# MCXN236 register map
Vendor: nxp.com; File version: 1.0
CPU: CM33 r2p0, little endian, MPU, FPU, VTOR, 3 interrupt priority bits
Registers are 32-bit, read-write, reset 0x0 unless marked. A register's access mark holds for its fields unless they carry their own. Offsets are from the block's base; [hi:lo] are bit positions; 'fields as' and 'values as' point back to an identical list; <NAME> marks a mode.

## USBPHY
Base 0x4010A000; alternate view of USBHS1_PHY_DCD
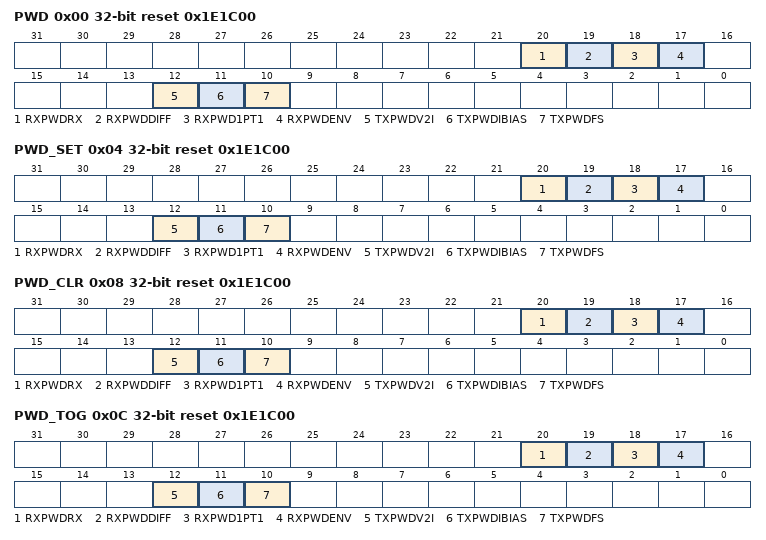
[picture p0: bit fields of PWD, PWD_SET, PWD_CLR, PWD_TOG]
0x00 PWD reset 0x1E1C00 — Power Down Register
  [20] RXPWDRX — Power down USBPHY receiver circuits except the FS differential comparator
    0=RX_BIAS_ENABLE (Enable the PHY's receiver block except for the FS differential receiver); 1=RX_BIAS_PWD (Power down the PHY's receiver block except for the FS differential receiver)
  [19] RXPWDDIFF — Power down USB HS differential receiver
    0=HS_RXDIFF_ENABLE (Enable the HS differential receiver); 1=HS_RXDIFF_PWD (Power down the HS differential receiver)
  [18] RXPWD1PT1 — Power down USB FS differential receiver
    0=FS_RXDIFF_ENABLE (Enable the FS differential receiver); 1=FS_RXDIFF_PWD (Power down the FS differential receiver)
  [17] RXPWDENV — Power down USB HS receiver envelope detector and Host Disconnect comparator
    0=RX_ENVHD_ENABLE (Enable the HS Rx envelope detector and Host Disconnect comparator); 1=RX_ENVHD_PWD (Power down the HS Rx envelope detector and Host Disconnect comparator)
  [12] TXPWDV2I — Power down USBPHY V-I converter and current mirror
    0=V2I_BIAS_ENABLE (Enable Tx V-to-I converter and current mirrors); 1=V2I_BIAS_PWD (Power down Tx V-to-I converter and current mirrors)
  [11] TXPWDIBIAS — Power down USBPHY current bias block
    0=IBIAS_ENABLE (Enable current mirror circuits for general transceiver/detector bias); 1=IBIAS_PWD (Power down current bias mirrors)
  [10] TXPWDFS — Power down USB FS drivers
    0=FSTX_BIAS_ENABLE (Provide bias to allow enable of FS Tx drivers); 1=FSTX_BIAS_PWD (Power down FS Tx drivers and configure them to high impedance state)
0x04 PWD_SET reset 0x1E1C00 write-1-sets — Power Down Register
  [20] RXPWDRX write-1-sets — Power down USBPHY receiver circuits except the FS differential comparator
  [19] RXPWDDIFF write-1-sets — Power down USB HS differential receiver
  [18] RXPWD1PT1 write-1-sets — Power down USB FS differential receiver
  [17] RXPWDENV write-1-sets — Power down USB HS receiver envelope detector and Host Disconnect comparator
  [12] TXPWDV2I write-1-sets — Power down USBPHY V-I converter and current mirror
  [11] TXPWDIBIAS write-1-sets — Power down USBPHY current bias block
  [10] TXPWDFS write-1-sets — Power down USB FS drivers
0x08 PWD_CLR reset 0x1E1C00 write-1-clears — Power Down Register
  [20] RXPWDRX write-1-clears — Power down USBPHY receiver circuits except the FS differential comparator
  [19] RXPWDDIFF write-1-clears — Power down USB HS differential receiver
  [18] RXPWD1PT1 write-1-clears — Power down USB FS differential receiver
  [17] RXPWDENV write-1-clears — Power down USB HS receiver envelope detector and Host Disconnect comparator
  [12] TXPWDV2I write-1-clears — Power down USBPHY V-I converter and current mirror
  [11] TXPWDIBIAS write-1-clears — Power down USBPHY current bias block
  [10] TXPWDFS write-1-clears — Power down USB FS drivers
0x0C PWD_TOG reset 0x1E1C00 write-1-toggles — Power Down Register
  [20] RXPWDRX write-1-toggles — Power down USBPHY receiver circuits except the FS differential comparator
  [19] RXPWDDIFF write-1-toggles — Power down USB HS differential receiver
  [18] RXPWD1PT1 write-1-toggles — Power down USB FS differential receiver
  [17] RXPWDENV write-1-toggles — Power down USB HS receiver envelope detector and Host Disconnect comparator
  [12] TXPWDV2I write-1-toggles — Power down USBPHY V-I converter and current mirror
  [11] TXPWDIBIAS write-1-toggles — Power down USBPHY current bias block
  [10] TXPWDFS write-1-toggles — Power down USB FS drivers
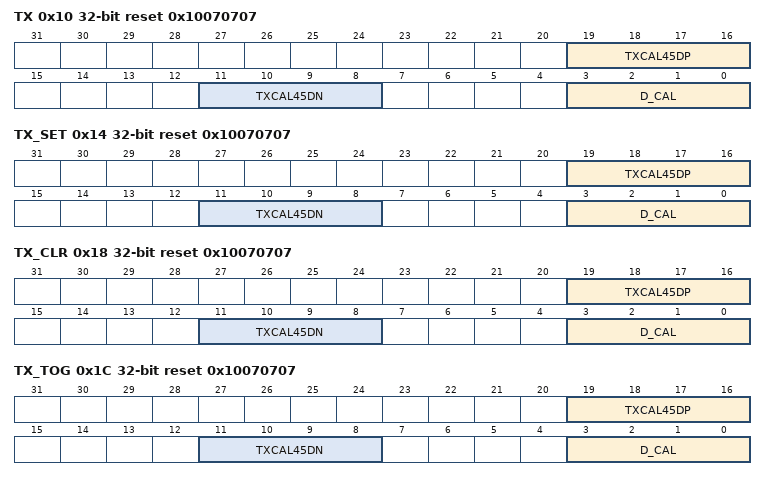
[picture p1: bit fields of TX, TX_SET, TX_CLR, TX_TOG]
0x10 TX reset 0x10070707 — Tx Control Register
  [19:16] TXCAL45DP — DP series termination resistance trim
  [11:8] TXCAL45DN — DM series termination resistance trim
  [3:0] D_CAL — HS Tx output current trim
0x14 TX_SET reset 0x10070707 write-1-sets — Tx Control Register
  [19:16] TXCAL45DP write-1-sets — DP series termination resistance trim
  [11:8] TXCAL45DN write-1-sets — DM series termination resistance trim
  [3:0] D_CAL write-1-sets — HS Tx output current trim
0x18 TX_CLR reset 0x10070707 write-1-clears — Tx Control Register
  [19:16] TXCAL45DP write-1-clears — DP series termination resistance trim
  [11:8] TXCAL45DN write-1-clears — DM series termination resistance trim
  [3:0] D_CAL write-1-clears — HS Tx output current trim
0x1C TX_TOG reset 0x10070707 write-1-toggles — Tx Control Register
  [19:16] TXCAL45DP write-1-toggles — DP series termination resistance trim
  [11:8] TXCAL45DN write-1-toggles — DM series termination resistance trim
  [3:0] D_CAL write-1-toggles — HS Tx output current trim
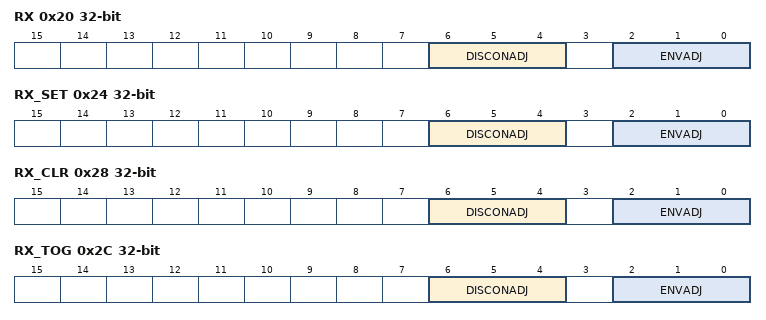
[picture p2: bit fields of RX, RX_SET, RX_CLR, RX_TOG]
0x20 RX — Rx Control Register
  [6:4] DISCONADJ — Disconnect detector trip point
    0=DISCON_TRIM_NOM (Trip-Level Voltage is 0.56875 V); 1=DISCON_TRIM_LO (Trip-Level Voltage is 0.55000 V); 2=DISCON_TRIM_MEDHI (Trip-Level Voltage is 0.58125 V); 3=DISCON_TRIM_HI (Trip-Level Voltage is 0.60000 V)
  [2:0] ENVADJ — Envelope detector trip point
    0=ENV_TRIM_NOM (Trip-Level Voltage is 0.1000 V); 1=ENV_TRIM_MEDHI (Trip-Level Voltage is 0.1125 V); 2=ENV_TRIM_HI (Trip-Level Voltage is 0.1250 V); 3=ENV_TRIM_LO (Trip-Level Voltage is 0.0875 V)
0x24 RX_SET write-1-sets — Rx Control Register
  [6:4] DISCONADJ write-1-sets — Disconnect detector trip point
  [2:0] ENVADJ write-1-sets — Envelope detector trip point
0x28 RX_CLR write-1-clears — Rx Control Register
  [6:4] DISCONADJ write-1-clears — Disconnect detector trip point
  [2:0] ENVADJ write-1-clears — Envelope detector trip point
0x2C RX_TOG write-1-toggles — Rx Control Register
  [6:4] DISCONADJ write-1-toggles — Disconnect detector trip point
  [2:0] ENVADJ write-1-toggles — Envelope detector trip point
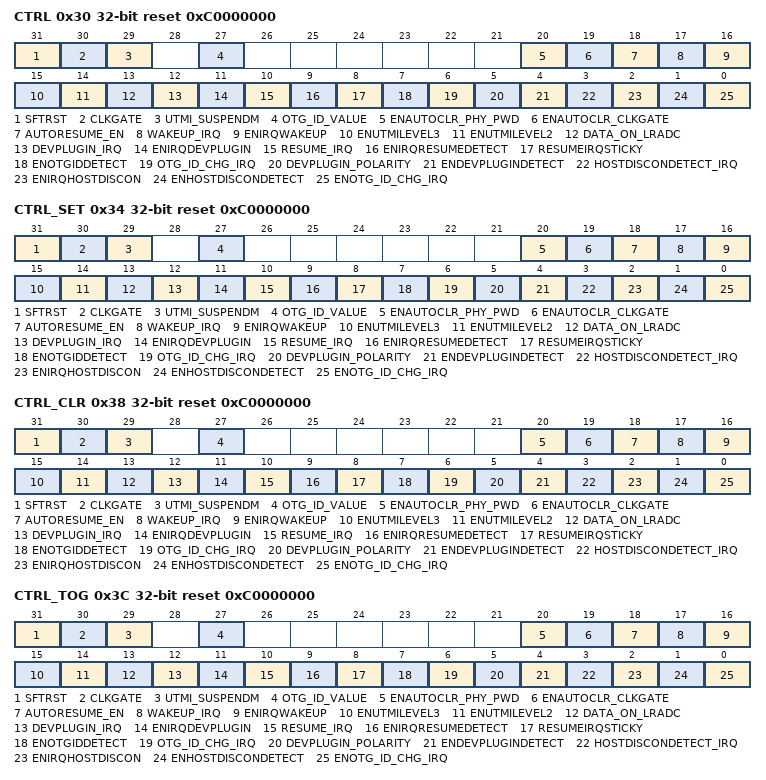
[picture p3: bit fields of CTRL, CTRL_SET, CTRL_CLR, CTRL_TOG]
0x30 CTRL reset 0xC0000000 — General Purpose Control Register
  [31] SFTRST — Software reset
  [30] CLKGATE — UTMI clock gate
  [29] UTMI_SUSPENDM ro — UTMI Suspend
  [27] OTG_ID_VALUE ro — ID value
    0=ID_HOST (False, when ID resistance to ground is less than Ra_Plug_ID, indicating Host (A) side); 1=ID_DEVICE (True, when ID resistance is greater than Rb_Plug_ID, indicating Device (B) side)
  [20] ENAUTOCLR_PHY_PWD — Autoclear PWD register bits
  [19] ENAUTOCLR_CLKGATE — Autoclear clock gate
  [18] AUTORESUME_EN — Enable autoresume
  [17] WAKEUP_IRQ
  [16] ENIRQWAKEUP — Enable Wakeup IRQ
  [15] ENUTMILEVEL3 — Enable level 3 operation
  [14] ENUTMILEVEL2 — Enable level 2 operation
  [13] DATA_ON_LRADC — APB clock switch option
  [12] DEVPLUGIN_IRQ — Device connected indicator for non-standard resistive plugged-in detection
  [11] ENIRQDEVPLUGIN — Enable IRQ for non-standard resistive plugged-in detection
  [10] RESUME_IRQ
  [9] ENIRQRESUMEDETECT — Enable IRQ Resume detect
  [8] RESUMEIRQSTICKY — Resume IRQ
  [7] ENOTGIDDETECT — Enable internal OTG ID detector
    0=ID_DET_DISABLE (Disable the PHY's internal ID pin detection circuit); 1=ID_DET_ENABLE (Enable the PHY's internal ID pin detection circuit)
  [6] OTG_ID_CHG_IRQ — OTG ID change IRQ
  [5] DEVPLUGIN_POLARITY — Device plugin polarity interrupt configuration for non-standard resistive plugged-in detection
  [4] ENDEVPLUGINDETECT — Enables non-standard resistive plugged-in detection
    0=PLUGIN_DISABLE (Disables 200 kohm pullup resistors on USB_DP and USB_DM pins); 1=PLUGIN_ENABLE (Enables 200 kohm pullup resistors on USB_DP and USB_DM pins)
  [3] HOSTDISCONDETECT_IRQ — Device disconnect indication
  [2] ENIRQHOSTDISCON — Enable IRQ for Host disconnect
  [1] ENHOSTDISCONDETECT — Disconnect detect
  [0] ENOTG_ID_CHG_IRQ — EN ID change IRQ
0x34 CTRL_SET reset 0xC0000000 write-1-sets — General Purpose Control Register
  [31] SFTRST write-1-sets — Software reset
  [30] CLKGATE write-1-sets — UTMI clock gate
  [29] UTMI_SUSPENDM ro write-1-sets — UTMI Suspend
  [27] OTG_ID_VALUE ro write-1-sets — ID value
  [20] ENAUTOCLR_PHY_PWD write-1-sets — Autoclear PWD register bits
  [19] ENAUTOCLR_CLKGATE write-1-sets — Autoclear clock gate
  [18] AUTORESUME_EN write-1-sets — Enable autoresume
  [17] WAKEUP_IRQ write-1-sets
  [16] ENIRQWAKEUP write-1-sets — Enable Wakeup IRQ
  [15] ENUTMILEVEL3 write-1-sets — Enable level 3 operation
  [14] ENUTMILEVEL2 write-1-sets — Enable level 2 operation
  [13] DATA_ON_LRADC write-1-sets — APB clock switch option
  [12] DEVPLUGIN_IRQ write-1-sets — Device connected indicator for non-standard resistive plugged-in detection
  [11] ENIRQDEVPLUGIN write-1-sets — Enable IRQ for non-standard resistive plugged-in detection
  [10] RESUME_IRQ write-1-sets
  [9] ENIRQRESUMEDETECT write-1-sets — Enable IRQ Resume detect
  [8] RESUMEIRQSTICKY write-1-sets — Resume IRQ
  [7] ENOTGIDDETECT write-1-sets — Enable internal OTG ID detector
  [6] OTG_ID_CHG_IRQ write-1-sets — OTG ID change IRQ
  [5] DEVPLUGIN_POLARITY write-1-sets — Device plugin polarity interrupt configuration for non-standard resistive plugged-in detection
  [4] ENDEVPLUGINDETECT write-1-sets — Enables non-standard resistive plugged-in detection
  [3] HOSTDISCONDETECT_IRQ write-1-sets — Device disconnect indication
  [2] ENIRQHOSTDISCON write-1-sets — Enable IRQ for Host disconnect
  [1] ENHOSTDISCONDETECT write-1-sets — Disconnect detect
  [0] ENOTG_ID_CHG_IRQ write-1-sets — EN ID change IRQ
0x38 CTRL_CLR reset 0xC0000000 write-1-clears — General Purpose Control Register
  [31] SFTRST write-1-clears — Software reset
  [30] CLKGATE write-1-clears — UTMI clock gate
  [29] UTMI_SUSPENDM ro write-1-clears — UTMI Suspend
  [27] OTG_ID_VALUE ro write-1-clears — ID value
  [20] ENAUTOCLR_PHY_PWD write-1-clears — Autoclear PWD register bits
  [19] ENAUTOCLR_CLKGATE write-1-clears — Autoclear clock gate
  [18] AUTORESUME_EN write-1-clears — Enable autoresume
  [17] WAKEUP_IRQ write-1-clears
  [16] ENIRQWAKEUP write-1-clears — Enable Wakeup IRQ
  [15] ENUTMILEVEL3 write-1-clears — Enable level 3 operation
  [14] ENUTMILEVEL2 write-1-clears — Enable level 2 operation
  [13] DATA_ON_LRADC write-1-clears — APB clock switch option
  [12] DEVPLUGIN_IRQ write-1-clears — Device connected indicator for non-standard resistive plugged-in detection
  [11] ENIRQDEVPLUGIN write-1-clears — Enable IRQ for non-standard resistive plugged-in detection
  [10] RESUME_IRQ write-1-clears
  [9] ENIRQRESUMEDETECT write-1-clears — Enable IRQ Resume detect
  [8] RESUMEIRQSTICKY write-1-clears — Resume IRQ
  [7] ENOTGIDDETECT write-1-clears — Enable internal OTG ID detector
  [6] OTG_ID_CHG_IRQ write-1-clears — OTG ID change IRQ
  [5] DEVPLUGIN_POLARITY write-1-clears — Device plugin polarity interrupt configuration for non-standard resistive plugged-in detection
  [4] ENDEVPLUGINDETECT write-1-clears — Enables non-standard resistive plugged-in detection
  [3] HOSTDISCONDETECT_IRQ write-1-clears — Device disconnect indication
  [2] ENIRQHOSTDISCON write-1-clears — Enable IRQ for Host disconnect
  [1] ENHOSTDISCONDETECT write-1-clears — Disconnect detect
  [0] ENOTG_ID_CHG_IRQ write-1-clears — EN ID change IRQ
0x3C CTRL_TOG reset 0xC0000000 write-1-toggles — General Purpose Control Register
  [31] SFTRST write-1-toggles — Software reset
  [30] CLKGATE write-1-toggles — UTMI clock gate
  [29] UTMI_SUSPENDM ro write-1-toggles — UTMI Suspend
  [27] OTG_ID_VALUE ro write-1-toggles — ID value
  [20] ENAUTOCLR_PHY_PWD write-1-toggles — Autoclear PWD register bits
  [19] ENAUTOCLR_CLKGATE write-1-toggles — Autoclear clock gate
  [18] AUTORESUME_EN write-1-toggles — Enable autoresume
  [17] WAKEUP_IRQ write-1-toggles
  [16] ENIRQWAKEUP write-1-toggles — Enable Wakeup IRQ
  [15] ENUTMILEVEL3 write-1-toggles — Enable level 3 operation
  [14] ENUTMILEVEL2 write-1-toggles — Enable level 2 operation
  [13] DATA_ON_LRADC write-1-toggles — APB clock switch option
  [12] DEVPLUGIN_IRQ write-1-toggles — Device connected indicator for non-standard resistive plugged-in detection
  [11] ENIRQDEVPLUGIN write-1-toggles — Enable IRQ for non-standard resistive plugged-in detection
  [10] RESUME_IRQ write-1-toggles
  [9] ENIRQRESUMEDETECT write-1-toggles — Enable IRQ Resume detect
  [8] RESUMEIRQSTICKY write-1-toggles — Resume IRQ
  [7] ENOTGIDDETECT write-1-toggles — Enable internal OTG ID detector
  [6] OTG_ID_CHG_IRQ write-1-toggles — OTG ID change IRQ
  [5] DEVPLUGIN_POLARITY write-1-toggles — Device plugin polarity interrupt configuration for non-standard resistive plugged-in detection
  [4] ENDEVPLUGINDETECT write-1-toggles — Enables non-standard resistive plugged-in detection
  [3] HOSTDISCONDETECT_IRQ write-1-toggles — Device disconnect indication
  [2] ENIRQHOSTDISCON write-1-toggles — Enable IRQ for Host disconnect
  [1] ENHOSTDISCONDETECT write-1-toggles — Disconnect detect
  [0] ENOTG_ID_CHG_IRQ write-1-toggles — EN ID change IRQ
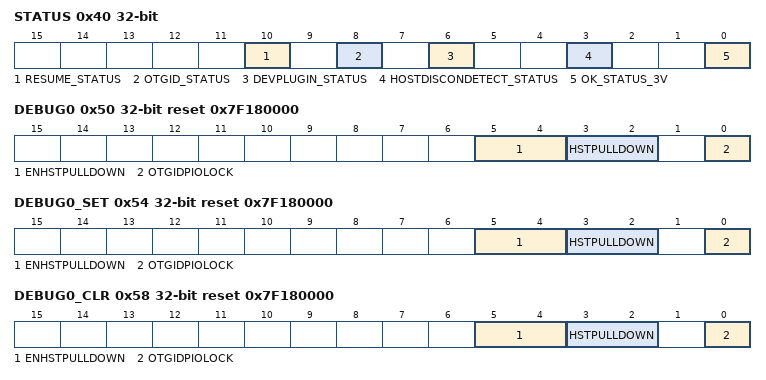
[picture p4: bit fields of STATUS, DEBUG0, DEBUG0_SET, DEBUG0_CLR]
0x40 STATUS (reset mask 0xFFFFFFFE)
  [10] RESUME_STATUS ro
  [8] OTGID_STATUS
    values as CTRL.OTG_ID_VALUE
  [6] DEVPLUGIN_STATUS ro — Status indicator for non-standard resistive plugged-in detection.
    0=NO_CABLE (No attachment to a USB Host is detected); 1=CABLE_ATTACH (Cable attachment to a USB Host is detected)
  [3] HOSTDISCONDETECT_STATUS ro — Host disconnect status
    0=NO_DISCONNECT (USB cable disconnect has not been detected at the local Host); 1=DISCONNECT (USB cable disconnect has been detected at the local Host)
  [0] OK_STATUS_3V ro — USB 3.3 V / 1.8 V supply status
    0=POWER_3_1P8_OK (One or both of the 1.8 V and 3.3 V supplies to the PHY are not powered); 1=POWER_3_1P8_BAD (Both of the 1.8 V and 3.3 V supplies to the PHY are powered)
0x50 DEBUG0 reset 0x7F180000 — Debug Register 0
  [5:4] ENHSTPULLDOWN — Enable Host pulldown overdrive mode
  [3:2] HSTPULLDOWN — Select DP/DM pulldown resistors in Host pulldown overdrive mode
  [0] OTGIDPIOLOCK — Hold OTG_ID
0x54 DEBUG0_SET reset 0x7F180000 write-1-sets — Debug Register 0
  [5:4] ENHSTPULLDOWN write-1-sets — Enable Host pulldown overdrive mode
  [3:2] HSTPULLDOWN write-1-sets — Select DP/DM pulldown resistors in Host pulldown overdrive mode
  [0] OTGIDPIOLOCK write-1-sets — Hold OTG_ID
0x58 DEBUG0_CLR reset 0x7F180000 write-1-clears — Debug Register 0
  [5:4] ENHSTPULLDOWN write-1-clears — Enable Host pulldown overdrive mode
  [3:2] HSTPULLDOWN write-1-clears — Select DP/DM pulldown resistors in Host pulldown overdrive mode
  [0] OTGIDPIOLOCK write-1-clears — Hold OTG_ID
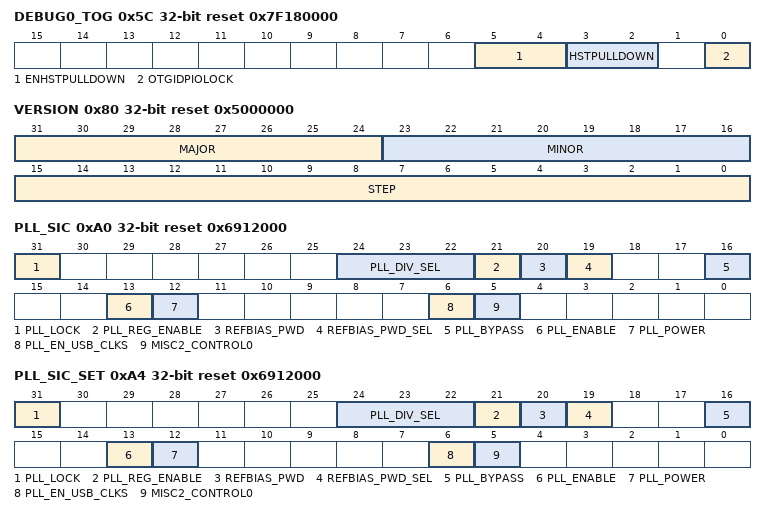
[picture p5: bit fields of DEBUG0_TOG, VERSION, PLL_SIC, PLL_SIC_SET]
0x5C DEBUG0_TOG reset 0x7F180000 write-1-toggles — Debug Register 0
  [5:4] ENHSTPULLDOWN write-1-toggles — Enable Host pulldown overdrive mode
  [3:2] HSTPULLDOWN write-1-toggles — Select DP/DM pulldown resistors in Host pulldown overdrive mode
  [0] OTGIDPIOLOCK write-1-toggles — Hold OTG_ID
0x80 VERSION ro reset 0x5000000
  [31:24] MAJOR, [23:16] MINOR, [15:0] STEP
0x90 IP reset 0x60000 — IP Block Register
  [0] POWER_CONTROL_SUSPEND_OPTION
0x94 IP_SET reset 0x60000 write-1-sets — IP Block Register
  [0] POWER_CONTROL_SUSPEND_OPTION write-1-sets
0x98 IP_CLR reset 0x60000 write-1-clears — IP Block Register
  [0] POWER_CONTROL_SUSPEND_OPTION write-1-clears
0x9C IP_TOG reset 0x60000 write-1-toggles — IP Block Register
  [0] POWER_CONTROL_SUSPEND_OPTION write-1-toggles
0xA0 PLL_SIC reset 0x6912000
  [31] PLL_LOCK ro — USB PLL lock status indicator
    0=PLL_NOT_LOCKED (The USB PLL is not currently locked); 1=PLL_LOCKED (The USB PLL is currently locked)
  [24:22] PLL_DIV_SEL — PLL divider value configuration
    0=PLL_DIV_15 (Configure for 32 MHz input clock (Divide by 15)); 1=PLL_DIV_16 (Configure for 30 MHz input clock (Divide by 16)); 2=PLL_DIV_20 (Configure for 24 MHz input clock (Divide by 20)); 4=PLL_DIV_24 (Configure for 20 MHz input clock (Divide by 24)); 5=PLL_DIV_25 (Configure for 19.2 MHz input clock (Divide by 25)); 6=PLL_DIV_30 (Configure for 16 MHz input clock (Divide by 30)); 7=PLL_DIV_32 (Configure for 12 MHz input clock (Divide by 40) May give marginal jitter results.)
  [21] PLL_REG_ENABLE — Enable PLL regulator
    0=PLL_REG_DISABLE (Disable the local regulator for the PLL); 1=PLL_REG_ENABLE (Enable the local regulator for the PLL)
  [20] REFBIAS_PWD — Power down reference bias
    0=REFBIAS_ENABLED (Enable master reference bias in direct power control mode); 1=REFBIAS_PWD (Power down master reference bias in direct power control mode)
  [19] REFBIAS_PWD_SEL — Reference bias power control
    0=BIAS_PLLPOWER (Control reference bias with PLL POWER internal state signal); 1=BIAS_REFBIAS_PWD (Control reference bias with PLL_SIC[REFBIAS_PWD])
  [16] PLL_BYPASS — Bypass USB PLL
    0=PLL_NO_BYPASS (Select PLL 480 MHz output clock for output mux); 1=PLL_BYPASS (Select PLL input reference clock for output mux)
  [13] PLL_ENABLE — PLL output clock enable
    0=PLL_OUT_DISABLE (Disable PLL single phase 480 MHz clock output); 1=PLL_OUT_ENABLE (Enable PLL single phase 480 MHz clock output)
  [12] PLL_POWER — USB PLL powerup control
    0=PLL_FORCE_PWD (Powers down the USB PLL); 1=PLL_ALLOW_POWERUP (Allows powerup of USB PLL)
  [6] PLL_EN_USB_CLKS — PLL multi-phase clock outputs enable
    0=PLL_MP_DISABLE (Disable PLL multi-phase 480 MHz clock outputs); 1=PLL_MP_ENABLE (Enable PLL multi-phase 480 MHz clock outputs)
  [5] MISC2_CONTROL0 — Determines USB PLL operation status during Suspend
    0=PLL_ON_SUSPEND (Power up PLL without regard to state of UTMI_SUSPENDM); 1=PLL_OFF_SUSPEND (Power down PLL when in Suspend bus state)
0xA4 PLL_SIC_SET reset 0x6912000 write-1-sets — PLL SIC Register
  [31] PLL_LOCK ro write-1-sets — USB PLL lock status indicator
  [24:22] PLL_DIV_SEL write-1-sets — PLL divider value configuration
  [21] PLL_REG_ENABLE write-1-sets — Enable PLL regulator
  [20] REFBIAS_PWD write-1-sets — Power down reference bias
  [19] REFBIAS_PWD_SEL write-1-sets — Reference bias power control
  [16] PLL_BYPASS write-1-sets — Bypass USB PLL
  [13] PLL_ENABLE write-1-sets — PLL output clock enable
  [12] PLL_POWER write-1-sets — USB PLL powerup control
  [6] PLL_EN_USB_CLKS write-1-sets — PLL multi-phase clock outputs enable
  [5] MISC2_CONTROL0 write-1-sets — Determines USB PLL operation status during Suspend
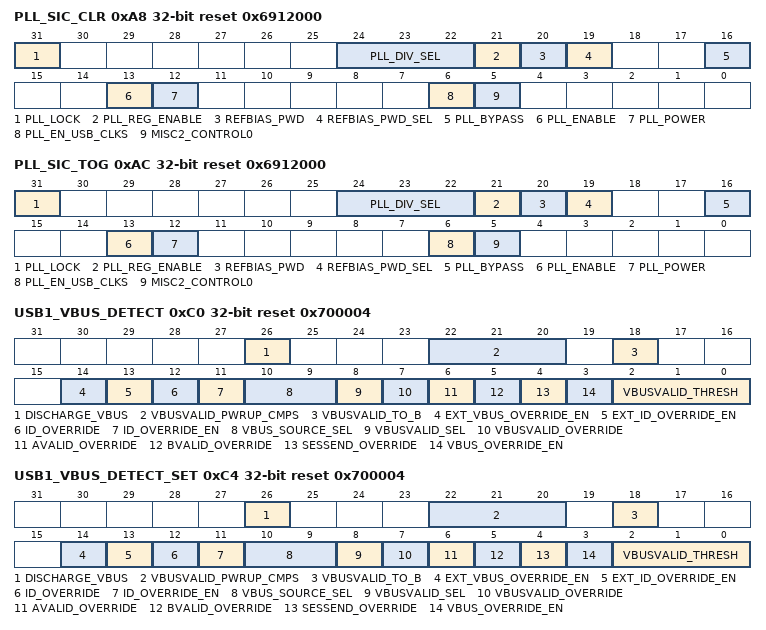
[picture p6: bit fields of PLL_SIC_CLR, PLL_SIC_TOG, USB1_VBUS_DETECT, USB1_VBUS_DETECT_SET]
0xA8 PLL_SIC_CLR reset 0x6912000 write-1-clears — PLL SIC Register
  [31] PLL_LOCK ro write-1-clears — USB PLL lock status indicator
  [24:22] PLL_DIV_SEL write-1-clears — PLL divider value configuration
  [21] PLL_REG_ENABLE write-1-clears — Enable PLL regulator
  [20] REFBIAS_PWD write-1-clears — Power down reference bias
  [19] REFBIAS_PWD_SEL write-1-clears — Reference bias power control
  [16] PLL_BYPASS write-1-clears — Bypass USB PLL
  [13] PLL_ENABLE write-1-clears — PLL output clock enable
  [12] PLL_POWER write-1-clears — USB PLL powerup control
  [6] PLL_EN_USB_CLKS write-1-clears — PLL multi-phase clock outputs enable
  [5] MISC2_CONTROL0 write-1-clears — Determines USB PLL operation status during Suspend
0xAC PLL_SIC_TOG reset 0x6912000 write-1-toggles — PLL SIC Register
  [31] PLL_LOCK ro write-1-toggles — USB PLL lock status indicator
  [24:22] PLL_DIV_SEL write-1-toggles — PLL divider value configuration
  [21] PLL_REG_ENABLE write-1-toggles — Enable PLL regulator
  [20] REFBIAS_PWD write-1-toggles — Power down reference bias
  [19] REFBIAS_PWD_SEL write-1-toggles — Reference bias power control
  [16] PLL_BYPASS write-1-toggles — Bypass USB PLL
  [13] PLL_ENABLE write-1-toggles — PLL output clock enable
  [12] PLL_POWER write-1-toggles — USB PLL powerup control
  [6] PLL_EN_USB_CLKS write-1-toggles — PLL multi-phase clock outputs enable
  [5] MISC2_CONTROL0 write-1-toggles — Determines USB PLL operation status during Suspend
0xC0 USB1_VBUS_DETECT reset 0x700004 — VBUS Detect Register
  [26] DISCHARGE_VBUS — Controls VBUS discharge resistor
    0=VBUS_DCHG_OFF (VBUS discharge resistor is disabled); 1=VBUS_DCHG_ON (VBUS discharge resistor is enabled)
  [22:20] VBUSVALID_PWRUP_CMPS — Individual enable controls for the VBUS detection comparators
    0bxx0=VBUS_VALID_DISABLE (Power down the VBUS_VALID comparator); 0bxx1=VBUS_VALID_ENABLE (Enable the VBUS_VALID comparator)
  [18] VBUSVALID_TO_B — Selects the comparator used for VBUS_VALID
    0=USE_VBUS_VLD (Use the VBUS_VALID comparator for VBUS_VALID results); 1=USE_SESS_VLD (Use the Session Valid detector for VBUS_VALID results. The Session Valid threshold is >= 0.8V and <= 4.0V.)
  [14] EXT_VBUS_OVERRIDE_EN — Enable external VBUS override using value supplied from outside the PHY
    0=USE_PHY_VBUS (Determine the reported VBUS detection results using the PHY's internal comparators/detectors or local overrides); 1=USB_EXT_VBUS (Determine the reported VBUS detection results using the external VBUS_VALID value)
  [13] EXT_ID_OVERRIDE_EN — Enable external ID pin status override using value supplied from outside the PHY
    0=USE_PHY_ID (Determine the reported ID pin status results using the PHY's internal detector or local override); 1=USE_EXT_ID (Determine the reported ID pin status results using the external ID signal value)
  [12] ID_OVERRIDE — ID pin status local override value
  [11] ID_OVERRIDE_EN — Enable local ID pin status override
    0=NO_PHY_ID_OVERRIDE (Use PHY's ID pin detector or external override for ID status); 1=USE_PHY_ID_OVERRIDE (Allow local override of ID pin detection status)
  [10:9] VBUS_SOURCE_SEL — Selects the source of the VBUS_VALID signal reported to the USB subsystem
    0=USE_VBUS_VLD (Use the VBUS_VALID comparator results for signal reported to the USB subsystem); 1=USE_ASESS_VLD (Use the Session Valid comparator results for signal reported to the USB subsystem); 2=USE_BSESS_VLD (Use the Session Valid comparator results for signal reported to the USB subsystem)
  [8] VBUSVALID_SEL — Selects the source of the VBUS_VALID signal reported to the USB subsystem
    0=VBUS_VLD_OUT (Use the VBUS_VALID comparator results for signal reported to the USB subsystem); 1=VBUS_VLD_3V_OUT (Use the VBUS_VALID_3V comparator results for signal reported to the USB subsystem)
  [7] VBUSVALID_OVERRIDE — Override value for VBUS_VALID signal sent to the USB subsystem
  [6] AVALID_OVERRIDE — Override value for A-Device Session Valid
  [5] BVALID_OVERRIDE — Override value for B-Device Session Valid
  [4] SESSEND_OVERRIDE — Override value for SESSEND
  [3] VBUS_OVERRIDE_EN — VBUS detect signal local override
    0=VBUS_NO_OVERRIDE (Use the results of the internal VBUS_VALID and Session Valid comparators for VBUS_VALID, AVALID, BVALID, and SESSEND); 1=VBUS_OVERRIDE (Use the override values for VBUS_VALID, AVALID, BVALID, and SESSEND)
  [2:0] VBUSVALID_THRESH — VBUS comparator threshold
    0=VBUS_VLD_4P0 (4.0 V); 1=VBUS_VLD_4P1 (4.1 V); 2=VBUS_VLD_4P2 (4.2 V); 3=VBUS_VLD_4P3 (4.3 V); 4=VBUS_VLD_4P4 (4.4 V (Default)); 5=VBUS_VLD_4P5 (4.5 V); 6=VBUS_VLD_4P6 (4.6 V); 7=VBUS_VLD_4P7 (4.7 V)
0xC4 USB1_VBUS_DETECT_SET reset 0x700004 write-1-sets — VBUS Detect Register
  [26] DISCHARGE_VBUS write-1-sets — Controls VBUS discharge resistor
  [22:20] VBUSVALID_PWRUP_CMPS write-1-sets — Individual enable controls for the VBUS detection comparators
  [18] VBUSVALID_TO_B write-1-sets — Selects the comparator used for VBUS_VALID
  [14] EXT_VBUS_OVERRIDE_EN write-1-sets — Enable external VBUS override using value supplied from outside the PHY
  [13] EXT_ID_OVERRIDE_EN write-1-sets — Enable external ID pin status override using value supplied from outside the PHY
  [12] ID_OVERRIDE write-1-sets — ID pin status local override value
  [11] ID_OVERRIDE_EN write-1-sets — Enable local ID pin status override
  [10:9] VBUS_SOURCE_SEL write-1-sets — Selects the source of the VBUS_VALID signal reported to the USB subsystem
  [8] VBUSVALID_SEL write-1-sets — Selects the source of the VBUS_VALID signal reported to the USB subsystem
  [7] VBUSVALID_OVERRIDE write-1-sets — Override value for VBUS_VALID signal sent to the USB subsystem
  [6] AVALID_OVERRIDE write-1-sets — Override value for A-Device Session Valid
  [5] BVALID_OVERRIDE write-1-sets — Override value for B-Device Session Valid
  [4] SESSEND_OVERRIDE write-1-sets — Override value for SESSEND
  [3] VBUS_OVERRIDE_EN write-1-sets — VBUS detect signal local override
  [2:0] VBUSVALID_THRESH write-1-sets — VBUS comparator threshold
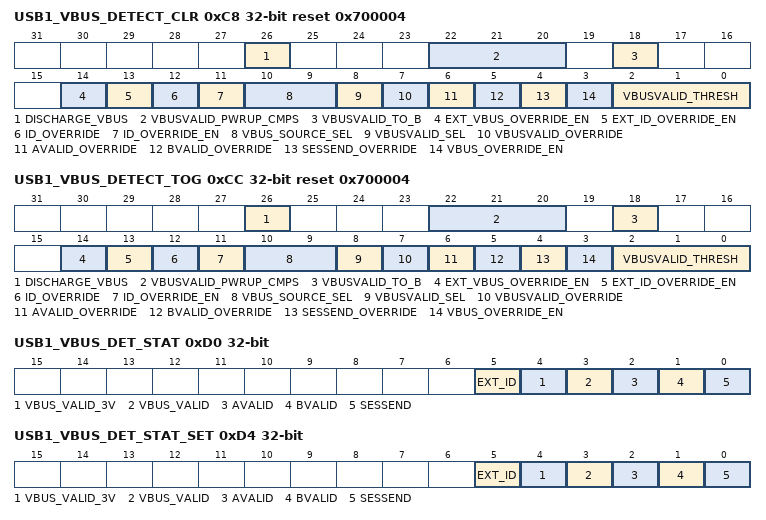
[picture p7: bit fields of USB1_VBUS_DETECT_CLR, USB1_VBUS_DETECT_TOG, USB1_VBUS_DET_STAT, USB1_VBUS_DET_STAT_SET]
0xC8 USB1_VBUS_DETECT_CLR reset 0x700004 write-1-clears — VBUS Detect Register
  [26] DISCHARGE_VBUS write-1-clears — Controls VBUS discharge resistor
  [22:20] VBUSVALID_PWRUP_CMPS write-1-clears — Individual enable controls for the VBUS detection comparators
  [18] VBUSVALID_TO_B write-1-clears — Selects the comparator used for VBUS_VALID
  [14] EXT_VBUS_OVERRIDE_EN write-1-clears — Enable external VBUS override using value supplied from outside the PHY
  [13] EXT_ID_OVERRIDE_EN write-1-clears — Enable external ID pin status override using value supplied from outside the PHY
  [12] ID_OVERRIDE write-1-clears — ID pin status local override value
  [11] ID_OVERRIDE_EN write-1-clears — Enable local ID pin status override
  [10:9] VBUS_SOURCE_SEL write-1-clears — Selects the source of the VBUS_VALID signal reported to the USB subsystem
  [8] VBUSVALID_SEL write-1-clears — Selects the source of the VBUS_VALID signal reported to the USB subsystem
  [7] VBUSVALID_OVERRIDE write-1-clears — Override value for VBUS_VALID signal sent to the USB subsystem
  [6] AVALID_OVERRIDE write-1-clears — Override value for A-Device Session Valid
  [5] BVALID_OVERRIDE write-1-clears — Override value for B-Device Session Valid
  [4] SESSEND_OVERRIDE write-1-clears — Override value for SESSEND
  [3] VBUS_OVERRIDE_EN write-1-clears — VBUS detect signal local override
  [2:0] VBUSVALID_THRESH write-1-clears — VBUS comparator threshold
0xCC USB1_VBUS_DETECT_TOG reset 0x700004 write-1-toggles — VBUS Detect Register
  [26] DISCHARGE_VBUS write-1-toggles — Controls VBUS discharge resistor
  [22:20] VBUSVALID_PWRUP_CMPS write-1-toggles — Individual enable controls for the VBUS detection comparators
  [18] VBUSVALID_TO_B write-1-toggles — Selects the comparator used for VBUS_VALID
  [14] EXT_VBUS_OVERRIDE_EN write-1-toggles — Enable external VBUS override using value supplied from outside the PHY
  [13] EXT_ID_OVERRIDE_EN write-1-toggles — Enable external ID pin status override using value supplied from outside the PHY
  [12] ID_OVERRIDE write-1-toggles — ID pin status local override value
  [11] ID_OVERRIDE_EN write-1-toggles — Enable local ID pin status override
  [10:9] VBUS_SOURCE_SEL write-1-toggles — Selects the source of the VBUS_VALID signal reported to the USB subsystem
  [8] VBUSVALID_SEL write-1-toggles — Selects the source of the VBUS_VALID signal reported to the USB subsystem
  [7] VBUSVALID_OVERRIDE write-1-toggles — Override value for VBUS_VALID signal sent to the USB subsystem
  [6] AVALID_OVERRIDE write-1-toggles — Override value for A-Device Session Valid
  [5] BVALID_OVERRIDE write-1-toggles — Override value for B-Device Session Valid
  [4] SESSEND_OVERRIDE write-1-toggles — Override value for SESSEND
  [3] VBUS_OVERRIDE_EN write-1-toggles — VBUS detect signal local override
  [2:0] VBUSVALID_THRESH write-1-toggles — VBUS comparator threshold
0xD0 USB1_VBUS_DET_STAT ro — VBUS Detect Status Register
  [5] EXT_ID — OTG ID external override status
  [4] VBUS_VALID_3V — VBUS_VALID_3V detector status
    0=VBUS_VLD3V_LO (VBUS voltage is below the VBUS_VALID_3V threshold); 1=VBUS_VLD3V_HI (VBUS voltage is above the VBUS_VALID_3V threshold)
  [3] VBUS_VALID — VBUS voltage status
    0=VBUS_LO (VBUS is below the comparator threshold); 1=VBUS_HI (VBUS is above the comparator threshold)
  [2] AVALID — A-Device Session Valid status
    0=AVALID_LO (The VBUS voltage is below the Session Valid threshold); 1=AVALID_HI (The VBUS voltage is above the Session Valid threshold)
  [1] BVALID — B-Device Session Valid status
    0=BVALID_LO (The VBUS voltage is below the Session Valid threshold); 1=BVALID_HI (The VBUS voltage is above the Session Valid threshold)
  [0] SESSEND — Session End indicator
    0=SESSEND_LO (The VBUS voltage is above the Session Valid threshold); 1=SESSEND_HI (The VBUS voltage is below the Session Valid threshold)
0xD4 USB1_VBUS_DET_STAT_SET ro write-1-sets — VBUS Detect Status Register
  [5] EXT_ID write-1-sets — OTG ID external override status
  [4] VBUS_VALID_3V write-1-sets — VBUS_VALID_3V detector status
  [3] VBUS_VALID write-1-sets — VBUS voltage status
  [2] AVALID write-1-sets — A-Device Session Valid status
  [1] BVALID write-1-sets — B-Device Session Valid status
  [0] SESSEND write-1-sets — Session End indicator
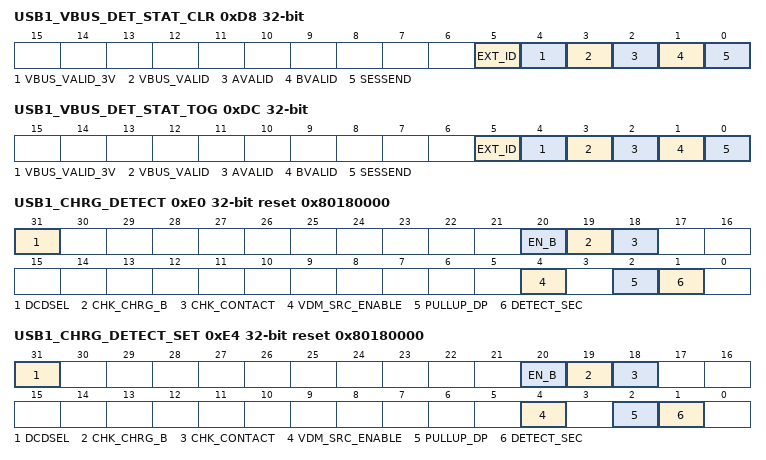
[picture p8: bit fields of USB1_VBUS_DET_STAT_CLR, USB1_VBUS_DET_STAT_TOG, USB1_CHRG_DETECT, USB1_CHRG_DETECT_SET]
0xD8 USB1_VBUS_DET_STAT_CLR ro write-1-clears — VBUS Detect Status Register
  [5] EXT_ID write-1-clears — OTG ID external override status
  [4] VBUS_VALID_3V write-1-clears — VBUS_VALID_3V detector status
  [3] VBUS_VALID write-1-clears — VBUS voltage status
  [2] AVALID write-1-clears — A-Device Session Valid status
  [1] BVALID write-1-clears — B-Device Session Valid status
  [0] SESSEND write-1-clears — Session End indicator
0xDC USB1_VBUS_DET_STAT_TOG ro write-1-toggles — VBUS Detect Status Register
  [5] EXT_ID write-1-toggles — OTG ID external override status
  [4] VBUS_VALID_3V write-1-toggles — VBUS_VALID_3V detector status
  [3] VBUS_VALID write-1-toggles — VBUS voltage status
  [2] AVALID write-1-toggles — A-Device Session Valid status
  [1] BVALID write-1-toggles — B-Device Session Valid status
  [0] SESSEND write-1-toggles — Session End indicator
0xE0 USB1_CHRG_DETECT reset 0x80180000 — Charger Detect Register
  [31] DCDSEL — Selects control source for Battery Charging Detection/Advertisement circuits
    0=CHRGDET_CTRL (Bit fields in USB1_CHRG_DETECT control BC 1.2 functionality); 1=USBHSDCD_CTRL (Bit fields and state machines in USBHSDCD module control BC 1.2 functionality)
  [20] EN_B — Enables selection of BC v1.2 functions depending on other bit fields (active low)
    0=BC_ENABLE (Enables BC v1.2 functions when controlled by this register); 1=BC_DISABLE (Disables BC v1.2 functions when controlled by this register)
  [19] CHK_CHRG_B — Enables BC v1.2 Primary Detection function for Charger Detect depending on other bit fields (active low)
    0=BC_CHRGDET_ENABLE (Enables BC Charger Detection function when controlled by this register); 1=BC_CHRGDET_DISABLE (Disables BC Charger Detection function when controlled by this register)
  [18] CHK_CONTACT — Enables BC v1.2 Data Contact Detect function for Charger Detect depending on other bit fields (active high)
    0=BC_DCD_DISABLE (Disables BC Data Contact Detect function when controlled by this register); 1=BC_DCD_ENABLE (Enables BC Data Contact Detect function when controlled by this register)
  [4] VDM_SRC_ENABLE — Enables BC v1.2 Charging Downstream Port (CDP) advertisement signaling for Charger Detect depending on other bit fields (active high).
    0=DCD_VDM_SRC_DISABLE (Disables CDP advertisement signaling VDM_SRC function when controlled by this register.); 1=DCD_VDM_SRC_ENABLE (Enables CDP advertisement signaling VDM_SRC function when controlled by this register.)
  [2] PULLUP_DP — DP pullup resistor enable override control
    0=DP_PUE_NORMAL (DP pullup resistor controlled only with UTMI bus signals); 1=DP_PUE_OVERRIDE (Force DP pullup resistor to be enabled)
  [1] DETECT_SEC — Enables BC v1.2 Secondary Detection function for Charger Detect depending on other bit fields (active high)
    0=BC_SECDET_DISABLE (Disables BC Secondary Detection function when controlled by this register); 1=BC_SECDET_ENABLE (Enables BC Secondary Detection function when controlled by this register)
0xE4 USB1_CHRG_DETECT_SET reset 0x80180000 write-1-sets — Charger Detect Register
  [31] DCDSEL write-1-sets — Selects control source for Battery Charging Detection/Advertisement circuits
  [20] EN_B write-1-sets — Enables selection of BC v1.2 functions depending on other bit fields (active low)
  [19] CHK_CHRG_B write-1-sets — Enables BC v1.2 Primary Detection function for Charger Detect depending on other bit fields (active low)
  [18] CHK_CONTACT write-1-sets — Enables BC v1.2 Data Contact Detect function for Charger Detect depending on other bit fields (active high)
  [4] VDM_SRC_ENABLE write-1-sets — Enables BC v1.2 Charging Downstream Port (CDP) advertisement signaling for Charger Detect depending on other bit fields (active high).
  [2] PULLUP_DP write-1-sets — DP pullup resistor enable override control
  [1] DETECT_SEC write-1-sets — Enables BC v1.2 Secondary Detection function for Charger Detect depending on other bit fields (active high)
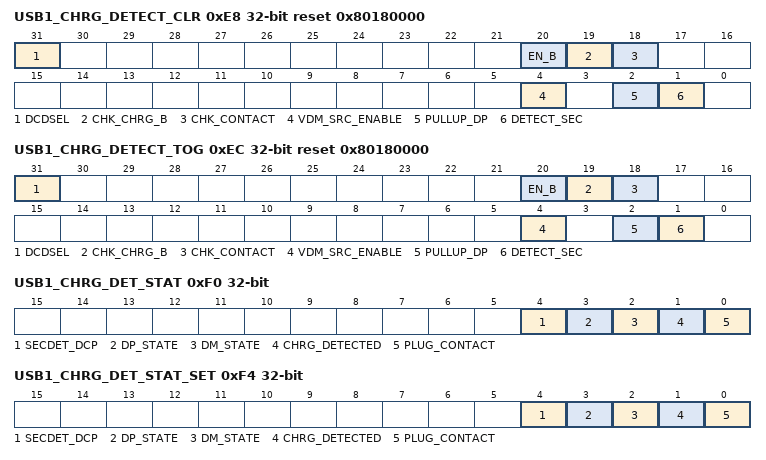
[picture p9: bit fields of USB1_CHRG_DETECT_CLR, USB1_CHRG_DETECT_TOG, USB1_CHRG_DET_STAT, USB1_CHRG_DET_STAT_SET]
0xE8 USB1_CHRG_DETECT_CLR reset 0x80180000 write-1-clears — Charger Detect Register
  [31] DCDSEL write-1-clears — Selects control source for Battery Charging Detection/Advertisement circuits
  [20] EN_B write-1-clears — Enables selection of BC v1.2 functions depending on other bit fields (active low)
  [19] CHK_CHRG_B write-1-clears — Enables BC v1.2 Primary Detection function for Charger Detect depending on other bit fields (active low)
  [18] CHK_CONTACT write-1-clears — Enables BC v1.2 Data Contact Detect function for Charger Detect depending on other bit fields (active high)
  [4] VDM_SRC_ENABLE write-1-clears — Enables BC v1.2 Charging Downstream Port (CDP) advertisement signaling for Charger Detect depending on other bit fields (active high).
  [2] PULLUP_DP write-1-clears — DP pullup resistor enable override control
  [1] DETECT_SEC write-1-clears — Enables BC v1.2 Secondary Detection function for Charger Detect depending on other bit fields (active high)
0xEC USB1_CHRG_DETECT_TOG reset 0x80180000 write-1-toggles — Charger Detect Register
  [31] DCDSEL write-1-toggles — Selects control source for Battery Charging Detection/Advertisement circuits
  [20] EN_B write-1-toggles — Enables selection of BC v1.2 functions depending on other bit fields (active low)
  [19] CHK_CHRG_B write-1-toggles — Enables BC v1.2 Primary Detection function for Charger Detect depending on other bit fields (active low)
  [18] CHK_CONTACT write-1-toggles — Enables BC v1.2 Data Contact Detect function for Charger Detect depending on other bit fields (active high)
  [4] VDM_SRC_ENABLE write-1-toggles — Enables BC v1.2 Charging Downstream Port (CDP) advertisement signaling for Charger Detect depending on other bit fields (active high).
  [2] PULLUP_DP write-1-toggles — DP pullup resistor enable override control
  [1] DETECT_SEC write-1-toggles — Enables BC v1.2 Secondary Detection function for Charger Detect depending on other bit fields (active high)
0xF0 USB1_CHRG_DET_STAT ro — Charger Detect Status Register
  [4] SECDET_DCP — Battery Charging Secondary Detection phase output
    0=SECDET_CDP (Charging Downstream Port (CDP) has been detected); 1=SECDET_DCP (Downstream Charging Port (DCP) has been detected)
  [3] DP_STATE — DP voltage
    0=DP_SERX_LO (USB_DP pin voltage is <= 0.8V); 1=DP_SERX_HI (USB_DP pin voltage is >= 2.0V)
  [2] DM_STATE — DM voltage
    0=DM_SERX_LO (USB_DM pin voltage is <= 0.8V); 1=DM_SERX_HI (USB_DM pin voltage is >= 2.0V)
  [1] CHRG_DETECTED — Battery Charging Primary Detection phase output
    0=SDP_DETECT (Standard Downstream Port (SDP) has been detected); 1=CHRG_PORT_DETECT (Charging Port has been detected)
  [0] PLUG_CONTACT — Battery Charging Data Contact Detection phase output
    0=NO_DC_DETECTED (No USB cable attachment has been detected); 1=DC_DETECED (A USB cable attachment between the device and host has been detected)
0xF4 USB1_CHRG_DET_STAT_SET ro write-1-sets — Charger Detect Status Register
  [4] SECDET_DCP write-1-sets — Battery Charging Secondary Detection phase output
  [3] DP_STATE write-1-sets — DP voltage
  [2] DM_STATE write-1-sets — DM voltage
  [1] CHRG_DETECTED write-1-sets — Battery Charging Primary Detection phase output
  [0] PLUG_CONTACT write-1-sets — Battery Charging Data Contact Detection phase output
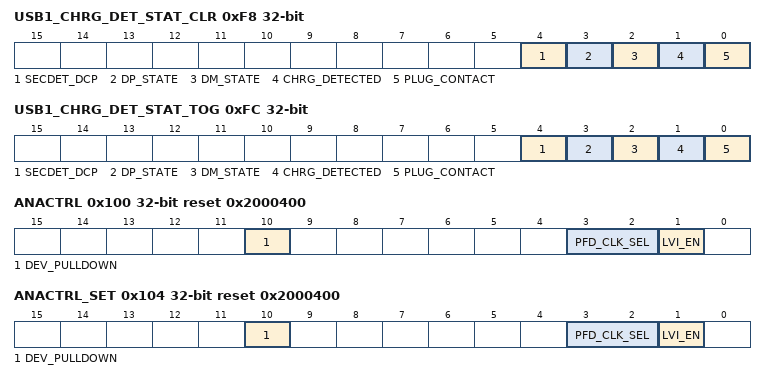
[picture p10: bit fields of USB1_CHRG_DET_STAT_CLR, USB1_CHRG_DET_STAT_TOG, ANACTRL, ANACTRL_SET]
0xF8 USB1_CHRG_DET_STAT_CLR ro write-1-clears — Charger Detect Status Register
  [4] SECDET_DCP write-1-clears — Battery Charging Secondary Detection phase output
  [3] DP_STATE write-1-clears — DP voltage
  [2] DM_STATE write-1-clears — DM voltage
  [1] CHRG_DETECTED write-1-clears — Battery Charging Primary Detection phase output
  [0] PLUG_CONTACT write-1-clears — Battery Charging Data Contact Detection phase output
0xFC USB1_CHRG_DET_STAT_TOG ro write-1-toggles — Charger Detect Status Register
  [4] SECDET_DCP write-1-toggles — Battery Charging Secondary Detection phase output
  [3] DP_STATE write-1-toggles — DP voltage
  [2] DM_STATE write-1-toggles — DM voltage
  [1] CHRG_DETECTED write-1-toggles — Battery Charging Primary Detection phase output
  [0] PLUG_CONTACT write-1-toggles — Battery Charging Data Contact Detection phase output
0x100 ANACTRL reset 0x2000400 — Analog Control Register
  [10] DEV_PULLDOWN — Device pulldown enable
    0=DEV_PULLDOWN_DIS (The 15 kohm nominal pulldowns on the USB_DP and USB_DM pins are disabled for Device mode); 1=DEV_PULLDOWN_EN (The 15 kohm nominal pulldowns on the USB_DP and USB_DM pins are enabled for Device mode)
  [3:2] PFD_CLK_SEL — PFD clock output mux control
    0=PFD_CLK_BYPASS (USB1PFDCLK is the same frequency as the USB PLL reference clock); 1=PFD_CLK_DIV_4 (USB1PFDCLK frequency is pfd_clk divided by 4); 2=PFD_CLK_DIV_2 (USB1PFDCLK frequency is pfd_clk divided by 2); 3=PFD_CLK_DIV_1 (USB1PFDCLK is the same as the pfd_clk frequency)
  [1] LVI_EN — LVI enable for USB 3.3 V monitor circuit
    0=LVI_3V_DISABLE (Disable the internal low voltage detector for the USB 3.3 V and 1.8 V domain); 1=LVI_3V_ENABLE (Enable the internal low voltage detector for the USB 3.3 V and 1.8 V domain)
0x104 ANACTRL_SET reset 0x2000400 write-1-sets — Analog Control Register
  [10] DEV_PULLDOWN write-1-sets — Device pulldown enable
  [3:2] PFD_CLK_SEL write-1-sets — PFD clock output mux control
  [1] LVI_EN write-1-sets — LVI enable for USB 3.3 V monitor circuit
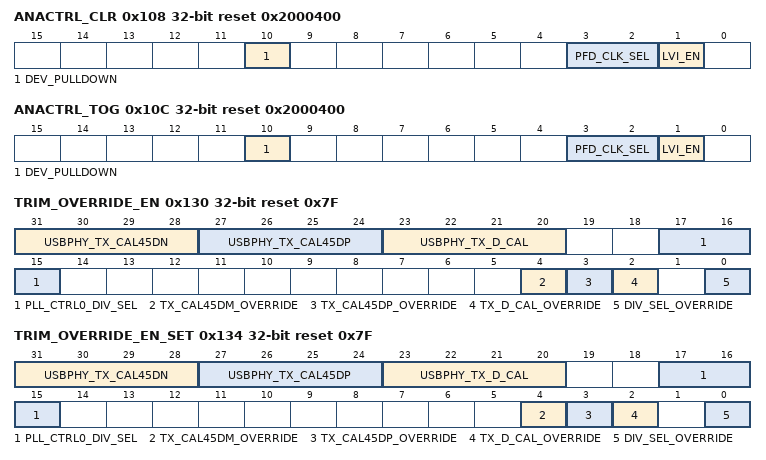
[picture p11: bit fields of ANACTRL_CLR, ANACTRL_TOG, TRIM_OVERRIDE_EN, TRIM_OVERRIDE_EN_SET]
0x108 ANACTRL_CLR reset 0x2000400 write-1-clears — Analog Control Register
  [10] DEV_PULLDOWN write-1-clears — Device pulldown enable
  [3:2] PFD_CLK_SEL write-1-clears — PFD clock output mux control
  [1] LVI_EN write-1-clears — LVI enable for USB 3.3 V monitor circuit
0x10C ANACTRL_TOG reset 0x2000400 write-1-toggles — Analog Control Register
  [10] DEV_PULLDOWN write-1-toggles — Device pulldown enable
  [3:2] PFD_CLK_SEL write-1-toggles — PFD clock output mux control
  [1] LVI_EN write-1-toggles — LVI enable for USB 3.3 V monitor circuit
0x130 TRIM_OVERRIDE_EN reset 0x7F — Trim Register
  [31:28] USBPHY_TX_CAL45DN ro — DM series termination resistance trim bits from outside USBPHY.
  [27:24] USBPHY_TX_CAL45DP ro — DP series termination resistance trim bits from outside USBPHY.
  [23:20] USBPHY_TX_D_CAL ro — HS Tx output current trim bits from outside USBPHY
  [17:15] PLL_CTRL0_DIV_SEL ro — PLL divider value configuration bits from outside USBPHY
  [4] TX_CAL45DM_OVERRIDE — Override enable for USB_DM series termination trim
    0=USE_TRIM0_CAL45DN (Use the TRIM_OVERRIDE_EN register values for DM resistance trim); 1=USE_TX_CAL45DN (Use the Tx register values for DM resistance trim)
  [3] TX_CAL45DP_OVERRIDE — Override enable for USB_DP series termination trim
    0=USE_TRIM0_CAL45DP (Use the TRIM_OVERRIDE_EN register values for DP resistance trim); 1=USE_TX_CAL45DP (Use the Tx register values for DP resistance trim)
  [2] TX_D_CAL_OVERRIDE — Override enable for HS Tx output current trim
    0=USE_TRIM0_DCAL (Use the TRIM_OVERRIDE_EN register values for HS Tx output current trim); 1=USE_TX_DCAL (Use the Tx register values for HS Tx output current trim)
  [0] DIV_SEL_OVERRIDE — Override enable for PLL divider value
    0=USE_TRIM0_PLLDIV (Use the TRIM_OVERRIDE_EN register values for the PLL divider value); 1=USE_PLL_SIC_PLLDIV (Use the PLL_SIC register values for the PLL divider value)
0x134 TRIM_OVERRIDE_EN_SET reset 0x7F write-1-sets — Trim Register
  [31:28] USBPHY_TX_CAL45DN ro write-1-sets — DM series termination resistance trim bits from outside USBPHY.
  [27:24] USBPHY_TX_CAL45DP ro write-1-sets — DP series termination resistance trim bits from outside USBPHY.
  [23:20] USBPHY_TX_D_CAL ro write-1-sets — HS Tx output current trim bits from outside USBPHY
  [17:15] PLL_CTRL0_DIV_SEL ro write-1-sets — PLL divider value configuration bits from outside USBPHY
  [4] TX_CAL45DM_OVERRIDE write-1-sets — Override enable for USB_DM series termination trim
  [3] TX_CAL45DP_OVERRIDE write-1-sets — Override enable for USB_DP series termination trim
  [2] TX_D_CAL_OVERRIDE write-1-sets — Override enable for HS Tx output current trim
  [0] DIV_SEL_OVERRIDE write-1-sets — Override enable for PLL divider value
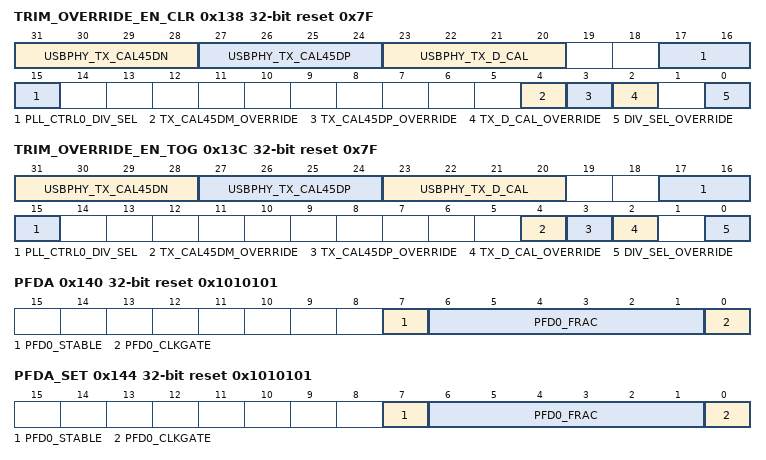
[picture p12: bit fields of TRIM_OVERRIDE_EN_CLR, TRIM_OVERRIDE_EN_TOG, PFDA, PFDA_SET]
0x138 TRIM_OVERRIDE_EN_CLR reset 0x7F write-1-clears — Trim Register
  [31:28] USBPHY_TX_CAL45DN ro write-1-clears — DM series termination resistance trim bits from outside USBPHY.
  [27:24] USBPHY_TX_CAL45DP ro write-1-clears — DP series termination resistance trim bits from outside USBPHY.
  [23:20] USBPHY_TX_D_CAL ro write-1-clears — HS Tx output current trim bits from outside USBPHY
  [17:15] PLL_CTRL0_DIV_SEL ro write-1-clears — PLL divider value configuration bits from outside USBPHY
  [4] TX_CAL45DM_OVERRIDE write-1-clears — Override enable for USB_DM series termination trim
  [3] TX_CAL45DP_OVERRIDE write-1-clears — Override enable for USB_DP series termination trim
  [2] TX_D_CAL_OVERRIDE write-1-clears — Override enable for HS Tx output current trim
  [0] DIV_SEL_OVERRIDE write-1-clears — Override enable for PLL divider value
0x13C TRIM_OVERRIDE_EN_TOG reset 0x7F write-1-toggles — Trim Register
  [31:28] USBPHY_TX_CAL45DN ro write-1-toggles — DM series termination resistance trim bits from outside USBPHY.
  [27:24] USBPHY_TX_CAL45DP ro write-1-toggles — DP series termination resistance trim bits from outside USBPHY.
  [23:20] USBPHY_TX_D_CAL ro write-1-toggles — HS Tx output current trim bits from outside USBPHY
  [17:15] PLL_CTRL0_DIV_SEL ro write-1-toggles — PLL divider value configuration bits from outside USBPHY
  [4] TX_CAL45DM_OVERRIDE write-1-toggles — Override enable for USB_DM series termination trim
  [3] TX_CAL45DP_OVERRIDE write-1-toggles — Override enable for USB_DP series termination trim
  [2] TX_D_CAL_OVERRIDE write-1-toggles — Override enable for HS Tx output current trim
  [0] DIV_SEL_OVERRIDE write-1-toggles — Override enable for PLL divider value
0x140 PFDA reset 0x1010101 — PFD Register A
  [7] PFD0_STABLE ro — PFD0 stable signal from the Phase Fractional Divider
  [6:1] PFD0_FRAC — PFD0 fractional divider setting used to select the pfd_clk output frequency
  [0] PFD0_CLKGATE — PFD0 clock gate
    0=PFD0_CLK_EN (PFD0 clock output is enabled); 1=PFD0_CLK_DIS (PFD0 clock output is gated (Default))
0x144 PFDA_SET reset 0x1010101 write-1-sets — PFD Register A
  [7] PFD0_STABLE ro write-1-sets — PFD0 stable signal from the Phase Fractional Divider
  [6:1] PFD0_FRAC write-1-sets — PFD0 fractional divider setting used to select the pfd_clk output frequency
  [0] PFD0_CLKGATE write-1-sets — PFD0 clock gate
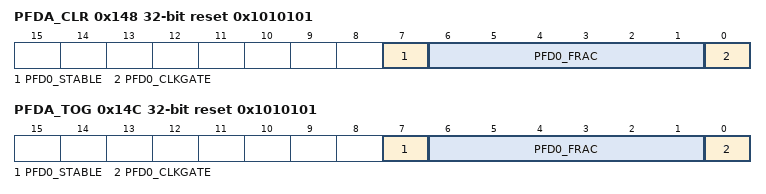
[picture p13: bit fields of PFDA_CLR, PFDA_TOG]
0x148 PFDA_CLR reset 0x1010101 write-1-clears — PFD Register A
  [7] PFD0_STABLE ro write-1-clears — PFD0 stable signal from the Phase Fractional Divider
  [6:1] PFD0_FRAC write-1-clears — PFD0 fractional divider setting used to select the pfd_clk output frequency
  [0] PFD0_CLKGATE write-1-clears — PFD0 clock gate
0x14C PFDA_TOG reset 0x1010101 write-1-toggles — PFD Register A
  [7] PFD0_STABLE ro write-1-toggles — PFD0 stable signal from the Phase Fractional Divider
  [6:1] PFD0_FRAC write-1-toggles — PFD0 fractional divider setting used to select the pfd_clk output frequency
  [0] PFD0_CLKGATE write-1-toggles — PFD0 clock gate
